# HC32F448 register map
File version: 1.0
CPU: CM4 r0p1, little endian, MPU, FPU, 4 interrupt priority bits
Registers are 32-bit, read-write, reset 0x0 unless marked. A register's access mark holds for its fields unless they carry their own. Offsets are from the block's base; [hi:lo] are bit positions; {n}, {i} and the like mark numbered series; 'fields as' and 'values as' point back to an identical list.

## RTC
Base 0x4004C000
0x00 CR0 8-bit
  [0] RESET
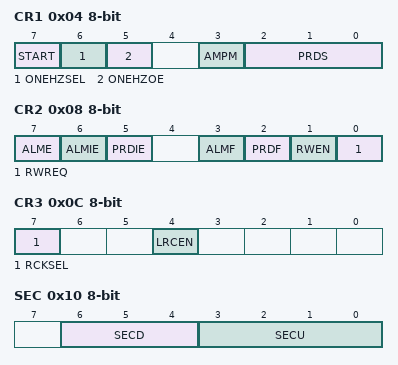
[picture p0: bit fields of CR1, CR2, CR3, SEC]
0x04 CR1 8-bit
  [7] START, [6] ONEHZSEL, [5] ONEHZOE, [3] AMPM, [2:0] PRDS
0x08 CR2 8-bit
  [7] ALME, [6] ALMIE, [5] PRDIE, [3] ALMF, [2] PRDF, [1] RWEN, [0] RWREQ
0x0C CR3 8-bit
  [7] RCKSEL, [4] LRCEN
0x10 SEC 8-bit
  [6:4] SECD, [3:0] SECU
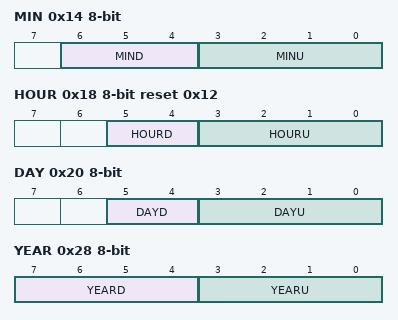
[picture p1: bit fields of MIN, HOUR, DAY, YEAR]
0x14 MIN 8-bit
  [6:4] MIND, [3:0] MINU
0x18 HOUR 8-bit reset 0x12
  [5:4] HOURD, [3:0] HOURU
0x1C WEEK 8-bit
  [2:0] WEEK
0x20 DAY 8-bit
  [5:4] DAYD, [3:0] DAYU
0x24 MON 8-bit
  [4:0] MON
0x28 YEAR 8-bit
  [7:4] YEARD, [3:0] YEARU
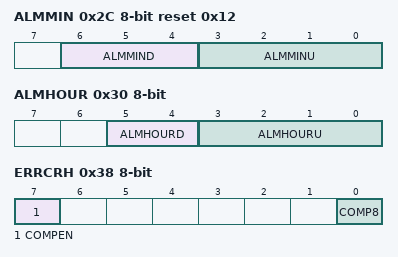
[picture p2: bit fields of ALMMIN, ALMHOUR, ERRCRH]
0x2C ALMMIN 8-bit reset 0x12
  [6:4] ALMMIND, [3:0] ALMMINU
0x30 ALMHOUR 8-bit
  [5:4] ALMHOURD, [3:0] ALMHOURU
0x34 ALMWEEK 8-bit
  [6:0] ALMWEEK
0x38 ERRCRH 8-bit
  [7] COMPEN, [0] COMP8
0x3C ERRCRL 8-bit reset 0x20

## SMC
Base 0x88000000
0x00 STSR ro reset 0x1
  [0] STATUS
0x08 STCR0 wo
  [2] LPWIR
0x0C STCR1 wo
  [2] LPWOR
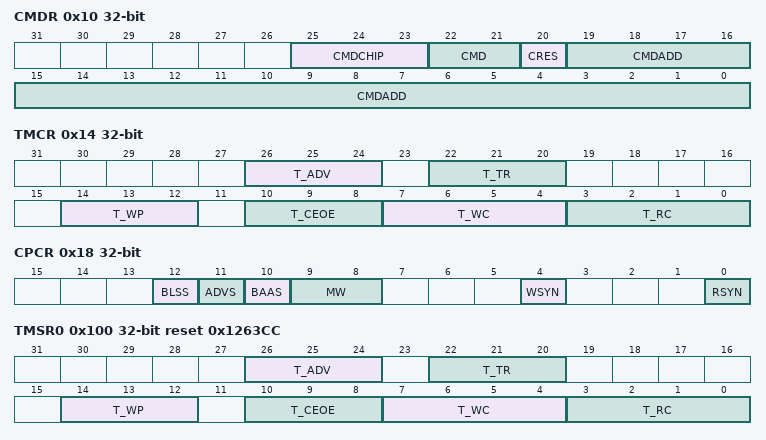
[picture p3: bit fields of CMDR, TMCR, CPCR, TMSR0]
0x10 CMDR wo
  [25:23] CMDCHIP, [22:21] CMD, [20] CRES, [19:0] CMDADD
0x14 TMCR wo
  [26:24] T_ADV, [22:20] T_TR, [14:12] T_WP, [10:8] T_CEOE, [7:4] T_WC, [3:0] T_RC
0x18 CPCR wo
  [12] BLSS, [11] ADVS, [10] BAAS, [9:8] MW, [4] WSYN, [0] RSYN
0x20 RFTR
  [3:0] REFPRD
0x100 TMSR0 ro reset 0x1263CC
  fields as TMCR
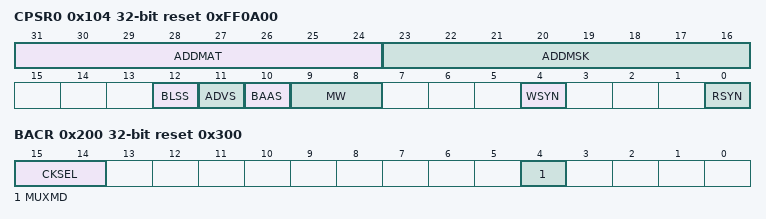
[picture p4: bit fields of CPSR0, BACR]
0x104 CPSR0 ro reset 0xFF0A00
  [31:24] ADDMAT, [23:16] ADDMSK, [12] BLSS, [11] ADVS, [10] BAAS, [9:8] MW, [4] WSYN, [0] RSYN
0x200 BACR reset 0x300
  [15:14] CKSEL, [4] MUXMD
0x208 CSCR0 reset 0xFFFFFFFF
  [7:0] ADDMSK0
0x20C CSCR1
  [7:0] ADDMAT0

## SPI1 — desc SPI
Base 0x4001C000
Same registers: SPI2 0x4001C400, SPI3 0x40020000
0x00 DR
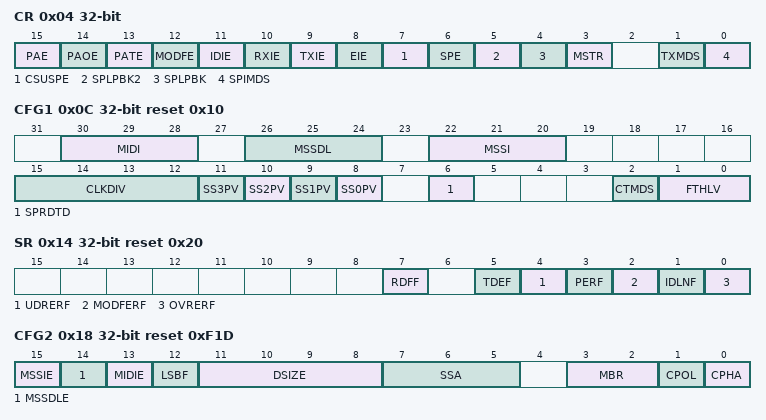
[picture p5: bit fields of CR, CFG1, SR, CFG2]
0x04 CR
  [15] PAE, [14] PAOE, [13] PATE, [12] MODFE, [11] IDIE, [10] RXIE, [9] TXIE, [8] EIE, [7] CSUSPE, [6] SPE, [5] SPLPBK2, [4] SPLPBK, [3] MSTR, [1] TXMDS, [0] SPIMDS
0x0C CFG1 reset 0x10
  [30:28] MIDI, [26:24] MSSDL, [22:20] MSSI, [15:12] CLKDIV, [n+8] SS{n}PV (n=0..3), [6] SPRDTD, [2] CTMDS, [1:0] FTHLV
0x14 SR reset 0x20
  [7] RDFF ro, [5] TDEF ro, [4] UDRERF, [3] PERF, [2] MODFERF, [1] IDLNF ro, [0] OVRERF
0x18 CFG2 reset 0xF1D
  [15] MSSIE, [14] MSSDLE, [13] MIDIE, [12] LSBF, [11:8] DSIZE, [7:5] SSA, [3:2] MBR, [1] CPOL, [0] CPHA

## SRAMC
Base 0x40050800
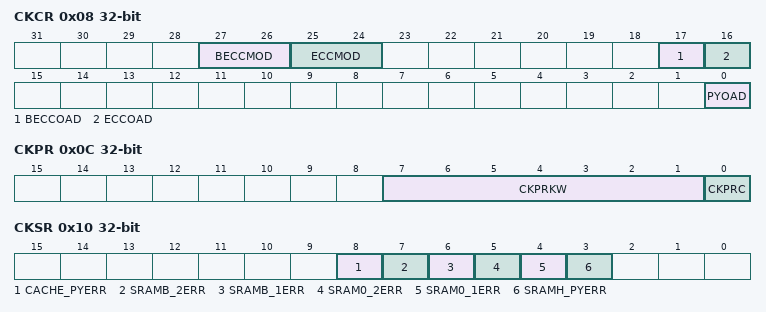
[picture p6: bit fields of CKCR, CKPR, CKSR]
0x08 CKCR
  [27:26] BECCMOD, [25:24] ECCMOD, [17] BECCOAD, [16] ECCOAD, [0] PYOAD
0x0C CKPR
  [7:1] CKPRKW, [0] CKPRC
0x10 CKSR
  [8] CACHE_PYERR, [7] SRAMB_2ERR, [6] SRAMB_1ERR, [5] SRAM0_2ERR, [4] SRAM0_1ERR, [3] SRAMH_PYERR
0x14 SRAM0_EIEN
  [0] EIEN
0x18 SRAM0_EIBIT0
0x1C SRAM0_EIBIT1
  [6:0] EIBIT
0x20 SRAM0_ECCERRADDR ro
  [14:0] ECCERRADDR
0x24 SRAMB_EIEN
  [0] EIEN
0x28 SRAMB_EIBIT0
0x2C SRAMB_EIBIT1
  [6:0] EIBIT
0x30 SRAMB_ECCERRADDR ro
  [11:0] ECCERRADDR

## SWDT
Base 0x40049400
Same registers: WDT 0x40049000
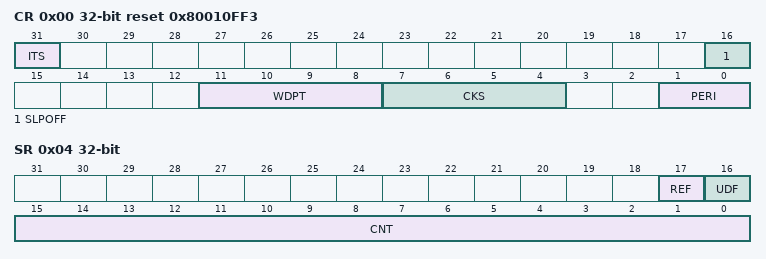
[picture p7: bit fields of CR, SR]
0x00 CR reset 0x80010FF3
  [31] ITS, [16] SLPOFF, [11:8] WDPT, [7:4] CKS, [1:0] PERI
0x04 SR
  [17] REF, [16] UDF, [15:0] CNT ro
0x08 RR
  [15:0] RF

## TMR01 — desc TMR0
Base 0x40024000
Same registers: TMR02 0x40024400
0x00 CNTAR
  [15:0] CNTA
0x04 CNTBR
  [15:0] CNTB
0x08 CMPAR reset 0xFFFF
  [15:0] CMPA
0x0C CMPBR reset 0xFFFF
  [15:0] CMPB
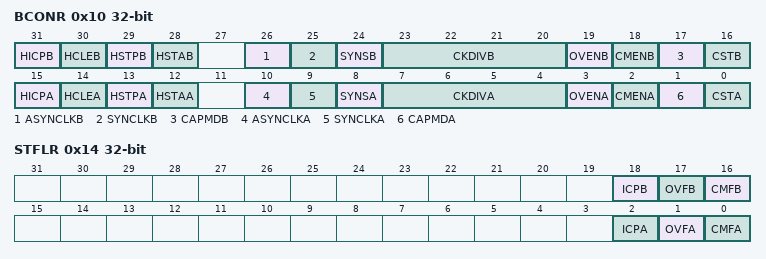
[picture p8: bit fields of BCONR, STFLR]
0x10 BCONR
  [31] HICPB, [30] HCLEB, [29] HSTPB, [28] HSTAB, [26] ASYNCLKB, [25] SYNCLKB, [24] SYNSB, [23:20] CKDIVB, [19] OVENB, [18] CMENB, [17] CAPMDB, [16] CSTB, [15] HICPA, [14] HCLEA, [13] HSTPA, [12] HSTAA, [10] ASYNCLKA, [9] SYNCLKA, [8] SYNSA, [7:4] CKDIVA, [3] OVENA, [2] CMENA, [1] CAPMDA, [0] CSTA
0x14 STFLR
  [18] ICPB, [17] OVFB, [16] CMFB, [2] ICPA, [1] OVFA, [0] CMFA

## TMR61 — desc TMR6
Base 0x4003C000
Same registers: TMR62 0x4003C400
0x00 CNTER
  [15:0] CNT
0x04 UPDAR
  [15:0] UPDA
0x40 PERAR reset 0xFFFFFFFF
  [15:0] PERA
0x44 PERBR reset 0xFFFFFFFF
  [15:0] PERB
0x48 PERCR reset 0xFFFFFFFF
  [15:0] PERC
0x80 GCMAR reset 0xFFFFFFFF
  [15:0] GCMA
0x84 GCMBR reset 0xFFFFFFFF
  [15:0] GCMB
0x88 GCMCR reset 0xFFFFFFFF
  [15:0] GCMC
0x8C GCMDR reset 0xFFFFFFFF
  [15:0] GCMD
0x90 GCMER reset 0xFFFFFFFF
  [15:0] GCME
0x94 GCMFR reset 0xFFFFFFFF
  [15:0] GCMF
0xC0 SCMAR reset 0xFFFFFFFF
  [15:0] SCMA
0xC4 SCMBR reset 0xFFFFFFFF
  [15:0] SCMB
0xC8 SCMCR reset 0xFFFFFFFF
  [15:0] SCMC
0xCC SCMDR reset 0xFFFFFFFF
  [15:0] SCMD
0xD0 SCMER reset 0xFFFFFFFF
  [15:0] SCME
0xD4 SCMFR reset 0xFFFFFFFF
  [15:0] SCMF
0x100 DTUAR reset 0xFFFFFFFF
  [15:0] DTUA
0x104 DTDAR reset 0xFFFFFFFF
  [15:0] DTDA
0x108 DTUBR reset 0xFFFFFFFF
  [15:0] DTUB
0x10C DTDBR reset 0xFFFFFFFF
  [15:0] DTDB
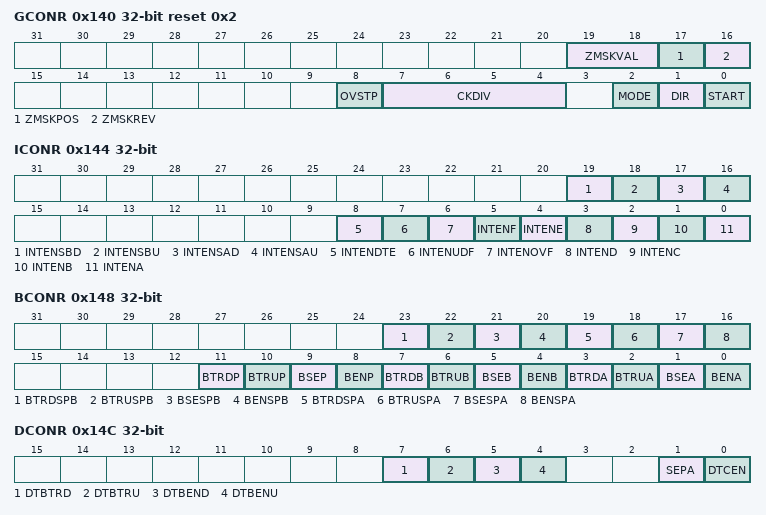
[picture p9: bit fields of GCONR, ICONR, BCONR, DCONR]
0x140 GCONR reset 0x2
  [19:18] ZMSKVAL, [17] ZMSKPOS, [16] ZMSKREV, [8] OVSTP, [7:4] CKDIV, [2] MODE, [1] DIR, [0] START
0x144 ICONR
  [19] INTENSBD, [18] INTENSBU, [17] INTENSAD, [16] INTENSAU, [8] INTENDTE, [7] INTENUDF, [6] INTENOVF, [5] INTENF, [4] INTENE, [3] INTEND, [2] INTENC, [1] INTENB, [0] INTENA
0x148 BCONR
  [23] BTRDSPB, [22] BTRUSPB, [21] BSESPB, [20] BENSPB, [19] BTRDSPA, [18] BTRUSPA, [17] BSESPA, [16] BENSPA, [11] BTRDP, [10] BTRUP, [9] BSEP, [8] BENP, [7] BTRDB, [6] BTRUB, [5] BSEB, [4] BENB, [3] BTRDA, [2] BTRUA, [1] BSEA, [0] BENA
0x14C DCONR
  [7] DTBTRD, [6] DTBTRU, [5] DTBEND, [4] DTBENU, [1] SEPA, [0] DTCEN
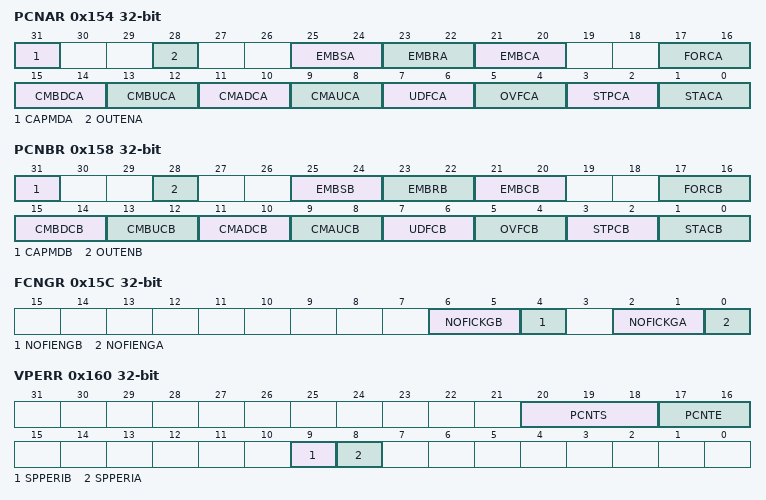
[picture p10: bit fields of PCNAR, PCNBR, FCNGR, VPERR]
0x154 PCNAR
  [31] CAPMDA, [28] OUTENA, [25:24] EMBSA, [23:22] EMBRA, [21:20] EMBCA, [17:16] FORCA, [15:14] CMBDCA, [13:12] CMBUCA, [11:10] CMADCA, [9:8] CMAUCA, [7:6] UDFCA, [5:4] OVFCA, [3:2] STPCA, [1:0] STACA
0x158 PCNBR
  [31] CAPMDB, [28] OUTENB, [25:24] EMBSB, [23:22] EMBRB, [21:20] EMBCB, [17:16] FORCB, [15:14] CMBDCB, [13:12] CMBUCB, [11:10] CMADCB, [9:8] CMAUCB, [7:6] UDFCB, [5:4] OVFCB, [3:2] STPCB, [1:0] STACB
0x15C FCNGR
  [6:5] NOFICKGB, [4] NOFIENGB, [2:1] NOFICKGA, [0] NOFIENGA
0x160 VPERR
  [20:18] PCNTS, [17:16] PCNTE, [9] SPPERIB, [8] SPPERIA
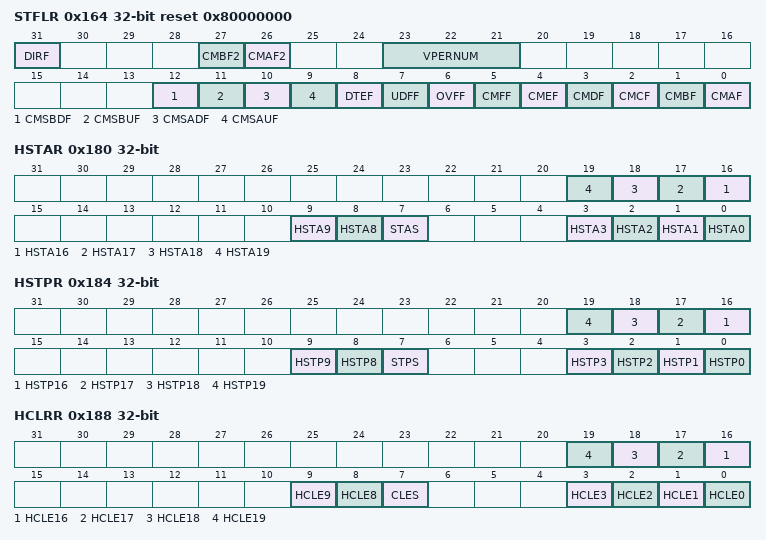
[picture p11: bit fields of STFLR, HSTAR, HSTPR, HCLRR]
0x164 STFLR reset 0x80000000
  [31] DIRF ro, [27] CMBF2, [26] CMAF2, [23:21] VPERNUM ro, [12] CMSBDF, [11] CMSBUF, [10] CMSADF, [9] CMSAUF, [8] DTEF ro, [7] UDFF, [6] OVFF, [5] CMFF, [4] CMEF, [3] CMDF, [2] CMCF, [1] CMBF, [0] CMAF
0x180 HSTAR
  [n] HSTA{n} (n=16..19), [9] HSTA9, [8] HSTA8, [7] STAS, [n] HSTA{n} (n=0..3)
0x184 HSTPR
  [n] HSTP{n} (n=16..19), [9] HSTP9, [8] HSTP8, [7] STPS, [n] HSTP{n} (n=0..3)
0x188 HCLRR
  [n] HCLE{n} (n=16..19), [9] HCLE9, [8] HCLE8, [7] CLES, [n] HCLE{n} (n=0..3)
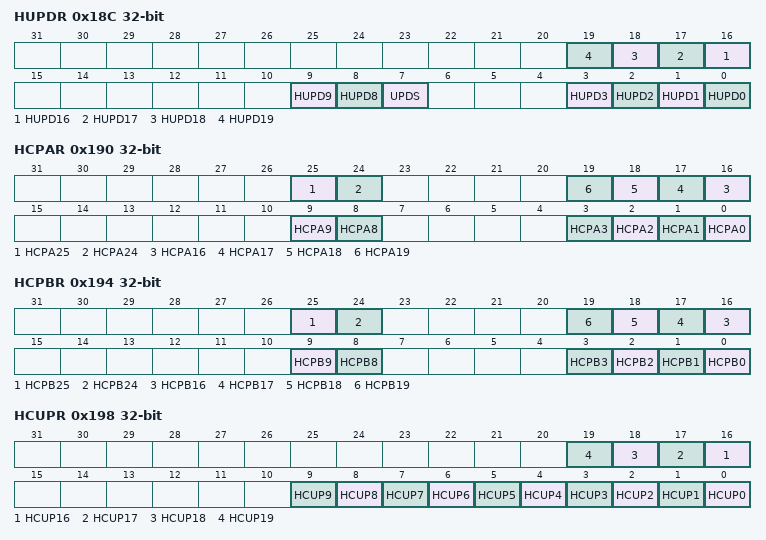
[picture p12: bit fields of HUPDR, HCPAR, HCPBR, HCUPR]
0x18C HUPDR
  [n] HUPD{n} (n=16..19), [9] HUPD9, [8] HUPD8, [7] UPDS, [n] HUPD{n} (n=0..3)
0x190 HCPAR
  [25] HCPA25, [24] HCPA24, [n] HCPA{n} (n=16..19), [9] HCPA9, [8] HCPA8, [n] HCPA{n} (n=0..3)
0x194 HCPBR
  [25] HCPB25, [24] HCPB24, [n] HCPB{n} (n=16..19), [9] HCPB9, [8] HCPB8, [n] HCPB{n} (n=0..3)
0x198 HCUPR
  [n] HCUP{n} (n=16..19), [n] HCUP{n} (n=0..9)
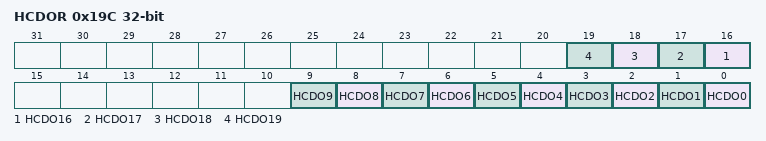
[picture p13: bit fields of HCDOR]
0x19C HCDOR
  [n] HCDO{n} (n=16..19), [n] HCDO{n} (n=0..9)

## TMR6_COMMON
Base 0x4003C300
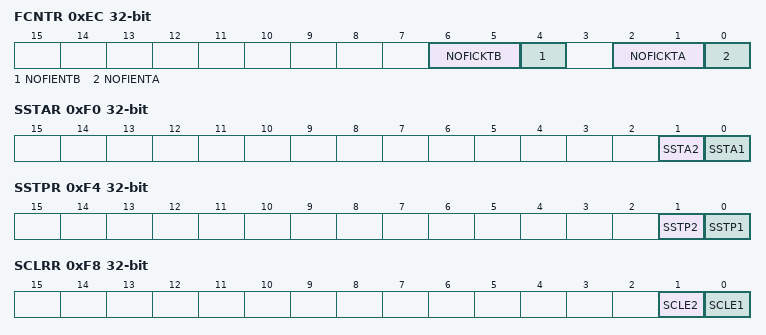
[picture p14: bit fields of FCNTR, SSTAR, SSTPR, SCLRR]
0xEC FCNTR
  [6:5] NOFICKTB, [4] NOFIENTB, [2:1] NOFICKTA, [0] NOFIENTA
0xF0 SSTAR
  [1] SSTA2, [0] SSTA1
0xF4 SSTPR
  [1] SSTP2, [0] SSTP1
0xF8 SCLRR
  [1] SCLE2, [0] SCLE1
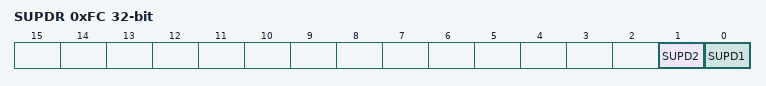
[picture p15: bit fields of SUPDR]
0xFC SUPDR
  [1] SUPD2, [0] SUPD1

## TMRA1 — desc TMRA
Base 0x4003A000
Same registers: TMRA5 0x40026000, TMRA2 0x4003A400, TMRA3 0x4003A800, TMRA4 0x4003AC00
0x00 CNTER
  [31:0] CNT
0x04 PERAR reset 0xFFFFFFFF
  [31:0] PER
{0x3C+4i} CMPAR{i} reset 0xFFFFFFFF (i=1..8)
  [31:0] CMP
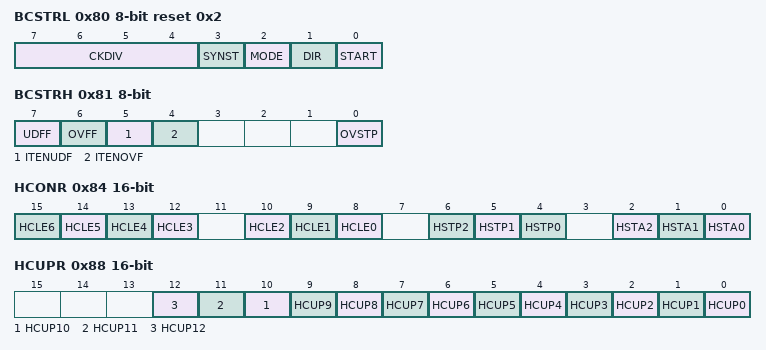
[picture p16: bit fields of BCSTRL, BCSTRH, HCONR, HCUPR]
0x80 BCSTRL 8-bit reset 0x2
  [7:4] CKDIV, [3] SYNST, [2] MODE, [1] DIR, [0] START
0x81 BCSTRH 8-bit
  [7] UDFF, [6] OVFF, [5] ITENUDF, [4] ITENOVF, [0] OVSTP
0x84 HCONR 16-bit
  [n+9] HCLE{n} (n=3..6), [10] HCLE2, [9] HCLE1, [8] HCLE0, [6] HSTP2, [5] HSTP1, [4] HSTP0, [2] HSTA2, [1] HSTA1, [0] HSTA0
0x88 HCUPR 16-bit
  [n] HCUP{n} (n=0..12)
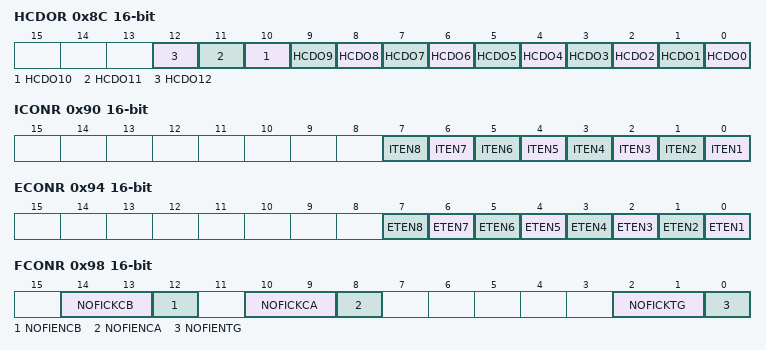
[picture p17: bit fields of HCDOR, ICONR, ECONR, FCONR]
0x8C HCDOR 16-bit
  [n] HCDO{n} (n=0..12)
0x90 ICONR 16-bit
  [n-1] ITEN{n} (n=1..8)
0x94 ECONR 16-bit
  [n-1] ETEN{n} (n=1..8)
0x98 FCONR 16-bit
  [14:13] NOFICKCB, [12] NOFIENCB, [10:9] NOFICKCA, [8] NOFIENCA, [2:1] NOFICKTG, [0] NOFIENTG
0x9C STFLR 16-bit
  [n+7] ICPF{n} (n=1..8), [n-1] CMPF{n} (n=1..8)
{0xB8+8i} BCONR{i} 16-bit (i=1..4)
  [3] BSEN, [2] BSE1, [1] BSE0, [0] BEN
{0xFC+4i} CCONR{i} 16-bit (i=1..8)
  [14:13] NOFICKCP, [12] NOFIENCP, [n+5] HICP{n} (n=3..6), [6] HICP2, [5] HICP1, [4] HICP0, [0] CAPMD
{0x13C+4i} PCONR{i} 16-bit (i=1..8)
  [12] OUTEN, [9:8] FORC, [7:6] PERC, [5:4] CMPC, [3:2] STPC, [1:0] STAC

## TRNG
Base 0x40042000
0x00 CR
  [1] RUN, [0] EN
0x04 MR reset 0x12
  [4:2] CNT, [0] LOAD
0x0C DR0 ro
0x10 DR1 ro

## USART1 — desc USART
Base 0x4001CC00
Same registers: USART2 0x4001D000, USART4 0x40020C00, USART5 0x40021000
0x00 SR ro reset 0xC0
  [16] MPB, [11] TEND, [8] RTOF, [7] TXE, [6] TC, [5] RXNE, [3] ORE, [1] FE, [0] PE
0x04 TDR 16-bit reset 0x1FF
  [9] MPID, [8:0] TDR
0x06 RDR 16-bit ro
  [8:0] RDR
0x08 BRR reset 0xFFFF
  [15:8] DIV_INTEGER, [6:0] DIV_FRACTION
0x0C CR1 reset 0x80000000
  [31] SBS, [30] NFE, [29] FBME, [28] ML, [25] CTEND, [24] MS, [20] CRTOF, [19] CORE, [17] CFE, [16] CPE, [15] OVER8, [12] M, [10] PCE, [9] PS, [8] TENDIE, [7] TXEIE, [6] TCIE, [5] RIE, [4] SLME, [3] TE, [2] RE, [1] RTOIE, [0] RTOE
0x10 CR2 reset 0x600
  [13] STOP, [12:11] CLKC, [0] MPE
0x14 CR3
  [23:21] BCN, [9] CTSE, [8] RTSE, [5] SCEN, [3] HDSEL
0x18 PR
  [4] ULBREN, [1:0] PSC

## USART3 — desc USART
Base 0x4001D400
Same registers: USART6 0x40021400
0x00 SR ro reset 0xC0
  [16] MPB, [11] TEND, [10] LBD, [9] WKUP, [7] TXE, [6] TC, [5] RXNE, [4] BE, [3] ORE, [1] FE, [0] PE
0x04 TDR 16-bit reset 0x1FF
  [9] MPID, [8:0] TDR
0x06 RDR 16-bit ro
  [8:0] RDR
0x08 BRR reset 0xFFFF
  [15:8] DIV_INTEGER, [6:0] DIV_FRACTION
0x0C CR1 reset 0x80000000
  [31] SBS, [30] NFE, [29] FBME, [28] ML, [25] CTEND, [24] MS, [23] CLBD, [22] CWKUP, [21] CBE, [19] CORE, [17] CFE, [16] CPE, [15] OVER8, [12] M, [10] PCE, [9] PS, [8] TENDIE, [7] TXEIE, [6] TCIE, [5] RIE, [4] SLME, [3] TE, [2] RE
0x10 CR2 reset 0x600
  [17] SBKM, [16] SBK, [14] LINEN, [13] STOP, [12:11] CLKC, [8] WKUPE, [7:6] SBKL, [5] LBDL, [4] LBDIE, [3] BEE, [2] BEIE, [1] WKUPIE, [0] MPE
0x14 CR3
  [9] CTSE, [8] RTSE, [4] LOOP, [3] HDSEL
0x18 PR
  [4] ULBREN, [3:2] LBMPSC, [1:0] PSC
0x1C LBMC ro
  [15:0] LBMC
